VERSION ""

NS_ :

BS_:

BU_: Node2 Node1

BO_ 2563309310 VehicleDataMulti: 12 Node1
 SG_ VehicleSignal6 : 80|16@1- (1,0) [0|0] ""  Node2
 SG_ VehicleSignal5 : 64|16@1- (1,0) [0|0] ""  Node2
 SG_ VehicleSignal4 : 48|16@1- (1,0) [0|0] ""  Node2
 SG_ VehicleSignal3 : 32|16@1- (1,0) [0|0] ""  Node2
 SG_ VehicleSignal2 : 16|16@1- (1,0) [0|0] ""  Node2
 SG_ VehicleSignal1 : 0|16@1- (1,0) [0|0] ""  Node2

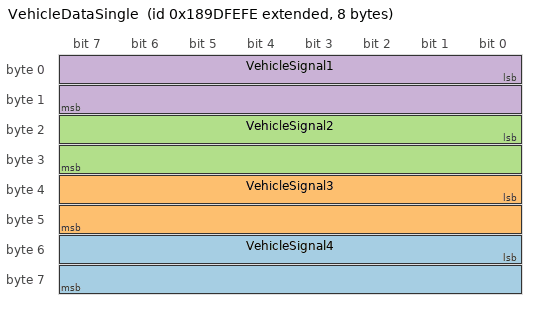
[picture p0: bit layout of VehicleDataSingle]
BO_ 2560491262 VehicleDataSingle: 8 Node1
 SG_ VehicleSignal4 : 48|16@1- (1,0) [0|0] ""  Node2
 SG_ VehicleSignal3 : 32|16@1- (1,0) [0|0] ""  Node2
 SG_ VehicleSignal2 : 16|16@1- (1,0) [0|0] ""  Node2
 SG_ VehicleSignal1 : 0|16@1- (1,0) [0|0] ""  Node2

BA_DEF_ SG_  "SigType" ENUM  "Default","Range","RangeSigned","ASCII","Discrete","Control","ReferencePGN","DTC","StringDelimiter","StringLength","StringLengthControl","MessageCounter","MessageChecksum";
BA_DEF_ SG_  "GenSigEVName" STRING ;
BA_DEF_ SG_  "GenSigILSupport" ENUM  "No","Yes";
BA_DEF_ SG_  "GenSigSendType" ENUM  "Cyclic","OnWrite","OnWriteWithRepetition","OnChange","OnChangeWithRepetition","IfActive","IfActiveWithRepetition","NoSigSendType";
BA_DEF_ BO_  "GenMsgILSupport" ENUM  "No","Yes";
BA_DEF_ BU_  "NmJ1939Function" INT 0 255;
BA_DEF_ BU_  "NmStationAddress" INT 0 255;
BA_DEF_ BO_  "GenMsgSendType" ENUM  "cyclic","NotUsed","IfActive","NotUsed","NotUsed","NotUsed","NotUsed","NotUsed","noMsgSendType";
BA_DEF_ BO_  "GenMsgRequestable" INT 0 1;
BA_DEF_  "DBName" STRING ;
BA_DEF_  "BusType" STRING ;
BA_DEF_  "ProtocolType" STRING ;
BA_DEF_ BO_  "VFrameFormat" ENUM  "StandardCAN","ExtendedCAN","reserved","J1939PG";
BA_DEF_DEF_  "SigType" "Default";
BA_DEF_DEF_  "GenSigEVName" "Env@Nodename_@Signame";
BA_DEF_DEF_  "GenSigILSupport" "Yes";
BA_DEF_DEF_  "GenSigSendType" "NoSigSendType";
BA_DEF_DEF_  "GenMsgILSupport" "Yes";
BA_DEF_DEF_  "NmJ1939Function" 0;
BA_DEF_DEF_  "NmStationAddress" 254;
BA_DEF_DEF_  "GenMsgSendType" "noMsgSendType";
BA_DEF_DEF_  "GenMsgRequestable" 1;
BA_DEF_DEF_  "DBName" "";
BA_DEF_DEF_  "BusType" "CAN";
BA_DEF_DEF_  "ProtocolType" "J1939";
BA_DEF_DEF_  "VFrameFormat" "J1939PG";
BA_ "DBName" "J1939";
BA_ "NmJ1939Function" BU_ Node2 8;
BA_ "NmStationAddress" BU_ Node2 50;
BA_ "NmJ1939Function" BU_ Node1 22;
BA_ "NmStationAddress" BU_ Node1 30;
